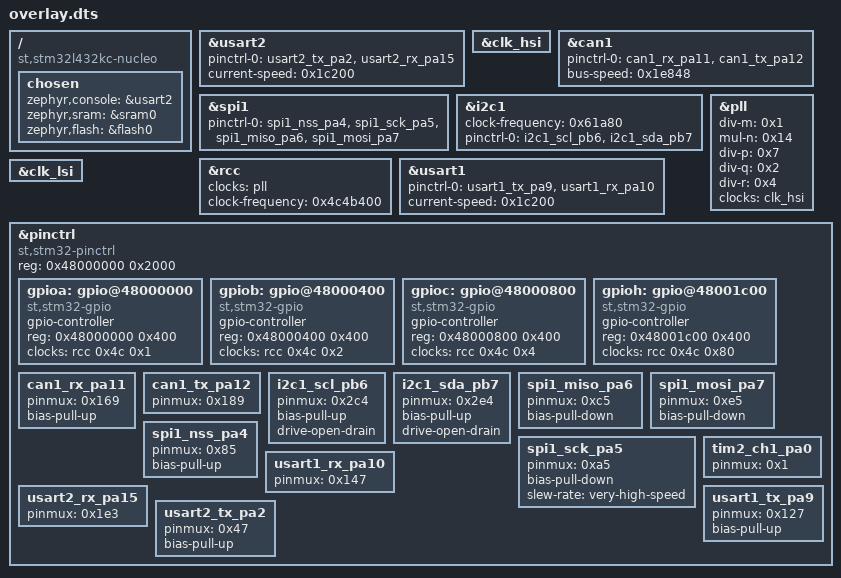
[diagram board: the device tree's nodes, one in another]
/ {
	compatible = "st,stm32l432kc-nucleo";
	chosen {
		zephyr,console = &usart2;
		zephyr,sram = &sram0;
		zephyr,flash = &flash0;
	};
};
&usart2{
	status = "okay";
	pinctrl-0 = < &usart2_tx_pa2 &usart2_rx_pa15 >;
	pinctrl-names = "default";
	current-speed = < 0x1c200 >;
};
&clk_hsi{
	status = "okay";
};
&can1{
	status = "okay";
	pinctrl-0 = < &can1_rx_pa11 &can1_tx_pa12 >;
	pinctrl-names = "default";
	bus-speed = < 0x1e848 >;
};
&spi1{
	status = "okay";
	pinctrl-0 = < &spi1_nss_pa4 &spi1_sck_pa5 &spi1_miso_pa6 &spi1_mosi_pa7 >;
	pinctrl-names = "default";
};
&i2c1{
	clock-frequency = < 0x61a80 >;
	status = "okay";
	pinctrl-0 = < &i2c1_scl_pb6 &i2c1_sda_pb7 >;
	pinctrl-names = "default";
};
&pll{
	status = "okay";
	div-m = < 0x1 >;
	mul-n = < 0x14 >;
	div-p = < 0x7 >;
	div-q = < 0x2 >;
	div-r = < 0x4 >;
	clocks = < &clk_hsi >;
};
&rcc{
	clocks = < &pll >;
	clock-frequency = < 0x4c4b400 >;
};
&usart1{
	pinctrl-0 = < &usart1_tx_pa9 &usart1_rx_pa10 >;
	pinctrl-names = "default";
	current-speed = < 0x1c200 >;
};
&clk_lsi{
	status = "okay";
};
&pinctrl{
	compatible = "st,stm32-pinctrl";
	#address-cells = < 0x1 >;
	#size-cells = < 0x1 >;
	reg = < 0x48000000 0x2000 >;
	gpioa: gpio@48000000 {
		compatible = "st,stm32-gpio";
		gpio-controller;
		#gpio-cells = < 0x2 >;
		reg = < 0x48000000 0x400 >;
		clocks = < &rcc 0x4c 0x1 >;
	};
	gpiob: gpio@48000400 {
		compatible = "st,stm32-gpio";
		gpio-controller;
		#gpio-cells = < 0x2 >;
		reg = < 0x48000400 0x400 >;
		clocks = < &rcc 0x4c 0x2 >;
	};
	gpioc: gpio@48000800 {
		compatible = "st,stm32-gpio";
		gpio-controller;
		#gpio-cells = < 0x2 >;
		reg = < 0x48000800 0x400 >;
		clocks = < &rcc 0x4c 0x4 >;
	};
	gpioh: gpio@48001c00 {
		compatible = "st,stm32-gpio";
		gpio-controller;
		#gpio-cells = < 0x2 >;
		reg = < 0x48001c00 0x400 >;
		clocks = < &rcc 0x4c 0x80 >;
	};
	can1_rx_pa11: can1_rx_pa11 {
		pinmux = < 0x169 >;
		bias-pull-up;
	};
	can1_tx_pa12: can1_tx_pa12 {
		pinmux = < 0x189 >;
	};
	i2c1_scl_pb6: i2c1_scl_pb6 {
		pinmux = < 0x2c4 >;
		bias-pull-up;
		drive-open-drain;
	};
	i2c1_sda_pb7: i2c1_sda_pb7 {
		pinmux = < 0x2e4 >;
		bias-pull-up;
		drive-open-drain;
	};
	spi1_miso_pa6: spi1_miso_pa6 {
		pinmux = < 0xc5 >;
		bias-pull-down;
	};
	spi1_mosi_pa7: spi1_mosi_pa7 {
		pinmux = < 0xe5 >;
		bias-pull-down;
	};
	spi1_nss_pa4: spi1_nss_pa4 {
		pinmux = < 0x85 >;
		bias-pull-up;
	};
	spi1_sck_pa5: spi1_sck_pa5 {
		pinmux = < 0xa5 >;
		bias-pull-down;
		slew-rate = "very-high-speed";
	};
	tim2_ch1_pa0: tim2_ch1_pa0 {
		pinmux = < 0x1 >;
	};
	usart1_rx_pa10: usart1_rx_pa10 {
		pinmux = < 0x147 >;
	};
	usart2_rx_pa15: usart2_rx_pa15 {
		pinmux = < 0x1e3 >;
	};
	usart1_tx_pa9: usart1_tx_pa9 {
		pinmux = < 0x127 >;
		bias-pull-up;
	};
	usart2_tx_pa2: usart2_tx_pa2 {
		pinmux = < 0x47 >;
		bias-pull-up;
	};
};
